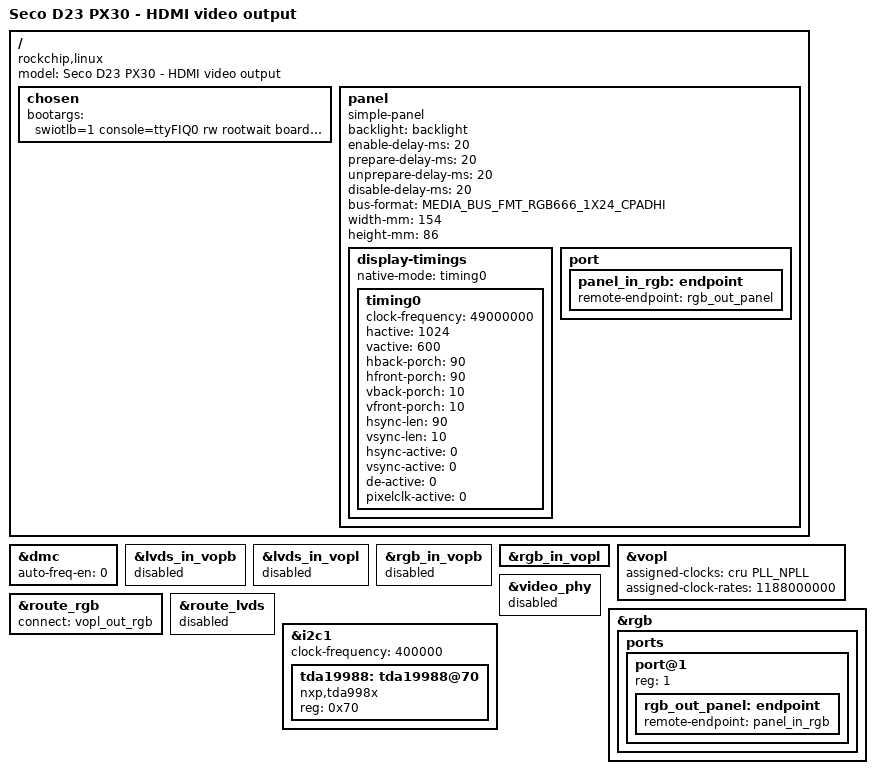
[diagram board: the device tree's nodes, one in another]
// SPDX-License-Identifier: (GPL-2.0+ OR MIT)
/*
 * Copyright (c) 2018 Fuzhou Rockchip Electronics Co., Ltd
 */

/dts-v1/;
#include "seco-px30-d23.dtsi"

/ {
	model = "Seco D23 PX30 - HDMI video output";
	compatible = "rockchip,linux", "rockchip,rk3326";

	chosen {
		bootargs = "swiotlb=1 console=ttyFIQ0 rw rootwait board_revA-HDMI";
	};

	panel {
		compatible = "simple-panel";
		backlight = <&backlight>;
		enable-delay-ms = <20>;
		prepare-delay-ms = <20>;
		unprepare-delay-ms = <20>;
		disable-delay-ms = <20>;
		bus-format = <MEDIA_BUS_FMT_RGB666_1X24_CPADHI>;

		width-mm = <154>;
		height-mm = <86>;

		display-timings {
			native-mode = <&timing0>;

			timing0: timing0 {
				clock-frequency = <49000000>;
				hactive = <1024>;
				vactive = <600>;
				hback-porch = <90>;
				hfront-porch = <90>;
				vback-porch = <10>;
				vfront-porch = <10>;
				hsync-len = <90>;
				vsync-len = <10>;
				hsync-active = <0>;
				vsync-active = <0>;
				de-active = <0>;
				pixelclk-active = <0>;
			};
		};

		port {
			panel_in_rgb: endpoint {
				remote-endpoint = <&rgb_out_panel>;
			};
		};
	};
};

&dmc {
	auto-freq-en = <0>;
};

&lvds_in_vopb {
	status = "disabled";
};

&lvds_in_vopl {
	status = "disabled";
};

&rgb_in_vopb {
	status = "disabled";
};

&rgb_in_vopl {
	status = "okay";
};

&vopl {
	assigned-clocks = <&cru PLL_NPLL>;
	assigned-clock-rates = <1188000000>;
	status = "okay";
};

&route_rgb {
	connect = <&vopl_out_rgb>;
	status = "okay";
};

&video_phy {
	status = "disabled";
};

&route_lvds {
	status = "disabled";
};

&rgb {
	status = "okay";
 
    ports {
        port@1 {
            reg = <1>;

            rgb_out_panel: endpoint {
                remote-endpoint = <&panel_in_rgb>;
            };
        };
    };

//    ports {
//        #address-cells = <1>;
//        #size-cells = <0>;
//
//        port@0 {
//            reg = <0>;
//            #address-cells = <1>;
//            #size-cells = <0>;
//
//		    rgb_out_hdmi: endpoint@0 {
//                reg = <0>;
//			    remote-endpoint = <&hdmi_in_rgb>;
//            };
//        };
//    };
};

&i2c1 {
	status = "okay";
	clock-frequency = <400000>;

    tda19988: tda19988@70 {
        compatible = "nxp,tda998x";
        reg = <0x70>;

//        port {
//            hdmi_in_rgb: endpoint@0 {
//				remote-endpoint = <&rgb_out_hdmi>;
//            };
//        };
    };
};

